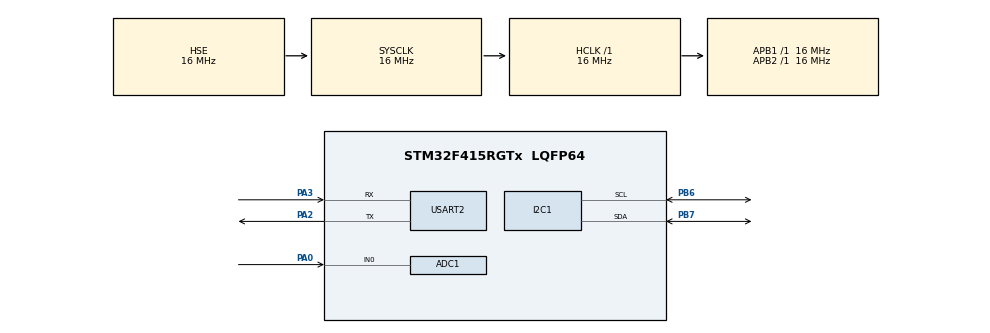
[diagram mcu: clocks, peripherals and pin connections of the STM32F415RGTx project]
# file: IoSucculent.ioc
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ADC1.Channel-0\#ChannelRegularConversion=ADC_CHANNEL_0
ADC1.NbrOfConversionFlag=1
ADC1.Rank-0\#ChannelRegularConversion=1
ADC1.SamplingTime-0\#ChannelRegularConversion=ADC_SAMPLETIME_3CYCLES
ADC1.master=1
Mcu.Family=STM32F4
Mcu.Name=STM32F415RGTx
Mcu.Package=LQFP64
NVIC.PriorityGroup=NVIC_PRIORITYGROUP_4
NVIC.RTC_Alarm_IRQn=true\:0\:0\:false\:false\:true\:true\:true\:true
NVIC.USART2_IRQn=true\:0\:0\:false\:false\:true\:true\:true\:true
PA0-WKUP.Signal=ADCx_IN0
PA13.Mode=Serial_Wire
PA13.Signal=SYS_JTMS-SWDIO
PA14.Mode=Serial_Wire
PA14.Signal=SYS_JTCK-SWCLK
PA2.Mode=Asynchronous
PA2.Signal=USART2_TX
PA3.Mode=Asynchronous
PA3.Signal=USART2_RX
PB6.Mode=I2C
PB6.Signal=I2C1_SCL
PB7.Mode=I2C
PB7.Signal=I2C1_SDA
PC14-OSC32_IN.Mode=LSE-External-Oscillator
PC14-OSC32_IN.Signal=RCC_OSC32_IN
PC15-OSC32_OUT.Mode=LSE-External-Oscillator
PC15-OSC32_OUT.Signal=RCC_OSC32_OUT
PH0-OSC_IN.Mode=HSE-External-Oscillator
PH0-OSC_IN.Signal=RCC_OSC_IN
PH1-OSC_OUT.Mode=HSE-External-Oscillator
PH1-OSC_OUT.Signal=RCC_OSC_OUT
ProjectManager.HeapSize=0x200
ProjectManager.StackSize=0x400
ProjectManager.TargetToolchain=STM32CubeIDE
RCC.AHBFreq_Value=16000000
RCC.APB1Freq_Value=16000000
RCC.APB2Freq_Value=16000000
RCC.CortexFreq_Value=16000000
RCC.HSE_VALUE=16000000
RCC.HSI_VALUE=16000000
RCC.RCC_RTC_Clock_Source=RCC_RTCCLKSOURCE_LSE
RCC.RCC_RTC_Clock_SourceVirtual=RCC_RTCCLKSOURCE_LSE
RCC.SYSCLKFreq_VALUE=16000000
RCC.SYSCLKSource=RCC_SYSCLKSOURCE_HSE
RCC.VCOOutputFreq_Value=192000000
RTC.Alarm=RTC_ALARM_A
RTC.AlarmMaskDateWeekDay=RTC_ALARMMASK_DATEWEEKDAY
RTC.AlarmMaskHours=RTC_ALARMMASK_HOURS
RTC.AlarmMaskMinutes=RTC_ALARMMASK_MINUTES
RTC.Date=15
RTC.Format=RTC_FORMAT_BIN
RTC.Hours=23
RTC.Minutes=56
RTC.Month=RTC_MONTH_OCTOBER
RTC.Seconds=0
RTC.WeekDay=RTC_WEEKDAY_WEDNESDAY
RTC.Year=25
SH.ADCx_IN0.0=ADC1_IN0,IN0
USART2.VirtualMode=VM_ASYNC
VP_RTC_VS_RTC_Activate.Mode=RTC_Enabled
VP_RTC_VS_RTC_Alarm_A_Intern.Mode=Alarm A
VP_RTC_VS_RTC_Calendar.Mode=RTC_Calendar
board=custom

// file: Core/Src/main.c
/* USER CODE BEGIN Header */
/**
  ******************************************************************************
  * @file           : main.c
  * @brief          : Main program body
  ******************************************************************************
  * @attention
  *
  * Copyright (c) 2025 STMicroelectronics.
  * All rights reserved.
  *
  * This software is licensed under terms that can be found in the LICENSE file
  * in the root directory of this software component.
  * If no LICENSE file comes with this software, it is provided AS-IS.
  *
  ******************************************************************************
  */
/* USER CODE END Header */
#include "main.h"
#include "adc.h"
#include "i2c.h"
#include "rtc.h"
#include "usart.h"
#include "gpio.h"

/* USER CODE BEGIN Includes */
#include "stdio.h"

/* USER CODE END Includes */

void SystemClock_Config(void);

/* USER CODE BEGIN 0 */
BMP280_HandleTypedef bme280;
/* USER CODE END 0 */

int main(void)
{

  /* MCU Configuration--------------------------------------------------------*/

  /* Reset of all peripherals, Initializes the Flash interface and the Systick. */
  HAL_Init();

  /* Configure the system clock */
  SystemClock_Config();

  /* Initialize all configured peripherals */
  MX_GPIO_Init();
  MX_USART2_UART_Init();
  MX_ADC1_Init();
  MX_I2C1_Init();
  MX_RTC_Init();
  /* USER CODE BEGIN 2 */

  // Start USART2 in interrupt mode
  HAL_UART_Receive_IT(&huart2, rx_input, 1);

  // Initialize BME280 with address 1110110 (0x76)
  bmp280_init_default_params(&bme280.params);
  bme280.addr = BMP280_I2C_ADDRESS_0;
  bme280.i2c = &hi2c1;

  while (!bmp280_init(&bme280, &bme280.params)) {
	  printf("BME280 initialization failed\n");
 	  HAL_Delay(5000);
  }
  /* USER CODE END 2 */

  /* Infinite loop */
  /* USER CODE BEGIN WHILE */
  while (1)
  {
	  //HAL_PWR_EnterSLEEPMode(PWR_MAINREGULATOR_ON, PWR_SLEEPENTRY_WFI);
    /* USER CODE END WHILE */

  }
}

void SystemClock_Config(void)
{
  RCC_OscInitTypeDef RCC_OscInitStruct = {0};
  RCC_ClkInitTypeDef RCC_ClkInitStruct = {0};

  /** Configure the main internal regulator output voltage
  */
  __HAL_RCC_PWR_CLK_ENABLE();
  __HAL_PWR_VOLTAGESCALING_CONFIG(PWR_REGULATOR_VOLTAGE_SCALE1);

  /** Initializes the RCC Oscillators according to the specified parameters
  * in the RCC_OscInitTypeDef structure.
  */
  RCC_OscInitStruct.OscillatorType = RCC_OSCILLATORTYPE_HSE|RCC_OSCILLATORTYPE_LSE;
  RCC_OscInitStruct.HSEState = RCC_HSE_ON;
  RCC_OscInitStruct.LSEState = RCC_LSE_ON;
  RCC_OscInitStruct.PLL.PLLState = RCC_PLL_NONE;
  if (HAL_RCC_OscConfig(&RCC_OscInitStruct) != HAL_OK)
  {
    Error_Handler();
  }

  /** Initializes the CPU, AHB and APB buses clocks
  */
  RCC_ClkInitStruct.ClockType = RCC_CLOCKTYPE_HCLK|RCC_CLOCKTYPE_SYSCLK
                              |RCC_CLOCKTYPE_PCLK1|RCC_CLOCKTYPE_PCLK2;
  RCC_ClkInitStruct.SYSCLKSource = RCC_SYSCLKSOURCE_HSE;
  RCC_ClkInitStruct.AHBCLKDivider = RCC_SYSCLK_DIV1;
  RCC_ClkInitStruct.APB1CLKDivider = RCC_HCLK_DIV1;
  RCC_ClkInitStruct.APB2CLKDivider = RCC_HCLK_DIV1;

  if (HAL_RCC_ClockConfig(&RCC_ClkInitStruct, FLASH_LATENCY_0) != HAL_OK)
  {
    Error_Handler();
  }
}

void Error_Handler(void)
{
  __disable_irq();
  while (1)
  {
  }
}
